AUTOSAR XML (schema 4-0-3)
package /ComponentTypes
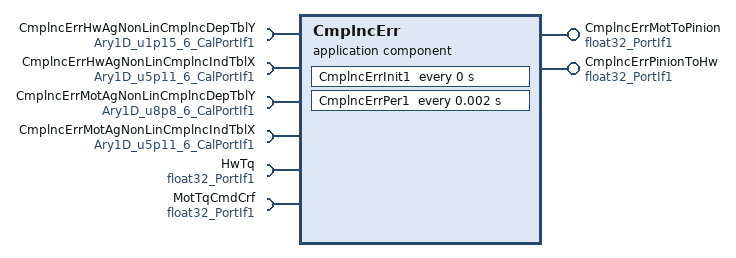
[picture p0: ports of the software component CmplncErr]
  application sw component type CmplncErr
    provide port CmplncErrMotToPinion: nonqueued-sender-com-spec{data-element=Val, init-value=0}, provided-interface=float32_PortIf1
    provide port CmplncErrPinionToHw: nonqueued-sender-com-spec{data-element=Val, init-value=0}, provided-interface=float32_PortIf1
    6 x require port:
      CmplncErrHwAgNonLinCmplncDepTblY: parameter-require-com-spec{init-value=6 x 0, parameter=Ary1D}, required-interface=Ary1D_u1p15_6_CalPortIf1
      CmplncErrHwAgNonLinCmplncIndTblX: parameter-require-com-spec{init-value=[0, 1024, 3072, 6144, 10240, 16384], parameter=Ary1D}, required-interface=Ary1D_u5p11_6_CalPortIf1
      CmplncErrMotAgNonLinCmplncDepTblY: parameter-require-com-spec{init-value=6 x 0, parameter=Ary1D}, required-interface=Ary1D_u8p8_6_CalPortIf1
      CmplncErrMotAgNonLinCmplncIndTblX: parameter-require-com-spec{init-value=[0, 1024, 3072, 6144, 10240, 16384], parameter=Ary1D}, required-interface=Ary1D_u5p11_6_CalPortIf1
      HwTq: nonqueued-receiver-com-spec{data-element=Val, filter=data-filter-type=ALWAYS, init-value=0}, required-interface=float32_PortIf1
      MotTqCmdCrf: nonqueued-receiver-com-spec{data-element=Val, filter=data-filter-type=ALWAYS, init-value=0}, required-interface=float32_PortIf1
    behavior CmplncErr_InternalBehavior
      timing event CmplncErrInit1_InitEvent: start-on-event=CmplncErrInit1, period=0
      timing event TMT_CmplncErrPer1: start-on-event=CmplncErrPer1, period=0.002
      runnable CmplncErrInit1
      runnable CmplncErrPer1
        data-receive-point-by-arguments:
          access REC_HwTq_Val: accessed-variable=HwTq.Val
          access REC_MotTqCmdCrf_Val: accessed-variable=MotTqCmdCrf.Val
        data-send-points:
          access SEND_CmplncErrMotToPinion_Val: accessed-variable=CmplncErrMotToPinion.Val
          access SEND_CmplncErrPinionToHw_Val: accessed-variable=CmplncErrPinionToHw.Val
  swc implementation CmplncErr_Implementation: behavior=CmplncErr_InternalBehavior
    code-descriptors:
      code Default: artifact-descriptors=autosar-engineering-object={short-label=Default, category=SWSRC}
